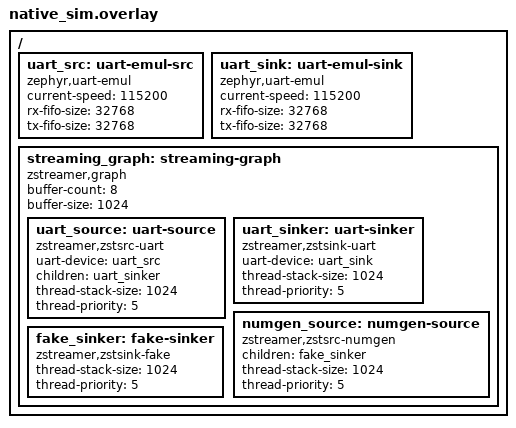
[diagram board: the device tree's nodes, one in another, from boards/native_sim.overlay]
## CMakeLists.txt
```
# Copyright (c) 2026 sharonthecreator
# SPDX-License-Identifier: Apache-2.0

cmake_minimum_required(VERSION 3.20.0)
find_package(Zephyr REQUIRED HINTS $ENV{ZEPHYR_BASE})
project(zstnode_test)

target_sources(app PRIVATE src/main.c)
```

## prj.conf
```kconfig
# Copyright (c) 2026 sharonthecreator
# SPDX-License-Identifier: Apache-2.0

CONFIG_ZTEST=y
CONFIG_ZSTREAMER=y
CONFIG_ZSTNODE=y
CONFIG_SERIAL=y
CONFIG_EMUL=y
CONFIG_UART_EMUL=y
CONFIG_LOG=y
```

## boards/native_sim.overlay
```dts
/*
 * Copyright (c) 2026 sharonthecreator
 * SPDX-License-Identifier: Apache-2.0
 */

/ {
	uart_src: uart-emul-src {
		compatible = "zephyr,uart-emul";
		current-speed = <115200>;
		rx-fifo-size = <32768>;
		tx-fifo-size = <32768>;
		status = "okay";
	};

	uart_sink: uart-emul-sink {
		compatible = "zephyr,uart-emul";
		current-speed = <115200>;
		rx-fifo-size = <32768>;
		tx-fifo-size = <32768>;
		status = "okay";
	};

	streaming_graph: streaming-graph {
		compatible = "zstreamer,graph";
		buffer-count = <8>;
		buffer-size = <1024>;

		uart_source: uart-source {
			compatible = "zstreamer,zstsrc-uart";
			uart-device = <&uart_src>;
			children = <&uart_sinker>;
			thread-stack-size = <1024>;
			thread-priority = <5>;
		};

		uart_sinker: uart-sinker {
			compatible = "zstreamer,zstsink-uart";
			uart-device = <&uart_sink>;
			thread-stack-size = <1024>;
			thread-priority = <5>;
		};

		numgen_source: numgen-source {
			compatible = "zstreamer,zstsrc-numgen";
			children = <&fake_sinker>;
			thread-stack-size = <1024>;
			thread-priority = <5>;
		};

		fake_sinker: fake-sinker {
			compatible = "zstreamer,zstsink-fake";
			thread-stack-size = <1024>;
			thread-priority = <5>;
		};
	};
};
```

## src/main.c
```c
/*
 * Copyright (c) 2026 zstreamer contributors
 * SPDX-License-Identifier: Apache-2.0
 */

#include <zephyr/ztest.h>
#include <zephyr/drivers/zstnode.h>

ZTEST_SUITE(zstnode, NULL, NULL, NULL, NULL, NULL);

ZTEST(zstnode, test_placeholder)
{
	ztest_test_pass();
}
```
